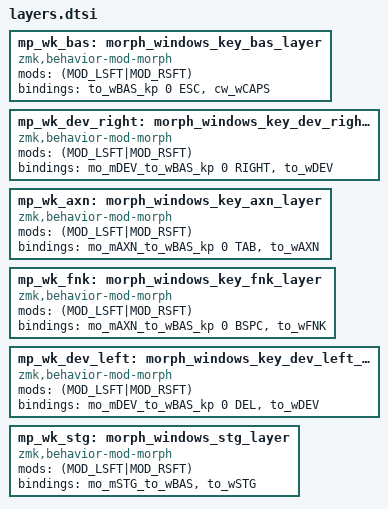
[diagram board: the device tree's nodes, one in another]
// tap:      escape      
// long-tap: to BAS layer
// shift:    caps lock
mp_wk_bas: morph_windows_key_bas_layer {
    compatible = "zmk,behavior-mod-morph";
    #binding-cells = <0>;
    mods = <(MOD_LSFT|MOD_RSFT)>;
    bindings = <&to_wBAS_kp 0 ESC>, <&cw_wCAPS>;
};

// tap:      right arrow       
// long-tap: to DEV momentary
// shift:    to DEV layer
mp_wk_dev_right: morph_windows_key_dev_right_layer {
    compatible = "zmk,behavior-mod-morph";
    #binding-cells = <0>;
    mods = <(MOD_LSFT|MOD_RSFT)>;
    bindings = <&mo_mDEV_to_wBAS_kp 0 RIGHT>, <&to_wDEV>;
};

// tap:      tab       
// long-tap: to AXN momentary
// shift:    to AXN layer
mp_wk_axn: morph_windows_key_axn_layer {
    compatible = "zmk,behavior-mod-morph";
    #binding-cells = <0>;
    mods = <(MOD_LSFT|MOD_RSFT)>;
    bindings = <&mo_mAXN_to_wBAS_kp 0 TAB>, <&to_wAXN>;
};

// tap:      backspace       
// long-tap: to AXN momentary
// shift:    to FNK layer
mp_wk_fnk: morph_windows_key_fnk_layer {
    compatible = "zmk,behavior-mod-morph";
    #binding-cells = <0>;
    mods = <(MOD_LSFT|MOD_RSFT)>;
    bindings = <&mo_mAXN_to_wBAS_kp 0 BSPC>, <&to_wFNK>;
};

// tap:      delete    
// long-tap: to DEV momentary
// shift:    to DEV layer
mp_wk_dev_left: morph_windows_key_dev_left_layer {
    compatible = "zmk,behavior-mod-morph";
    #binding-cells = <0>;
    mods = <(MOD_LSFT|MOD_RSFT)>;
    bindings = <&mo_mDEV_to_wBAS_kp 0 DEL>, <&to_wDEV>;
};

// long-tap: to STG momentary
// shift:    to STG layer
mp_wk_stg: morph_windows_stg_layer {
    compatible = "zmk,behavior-mod-morph";
    #binding-cells = <0>;
    mods = <(MOD_LSFT|MOD_RSFT)>;
    bindings = <&mo_mSTG_to_wBAS>, <&to_wSTG>;
};

